# tviic2d6mddr register map
Vendor: Cypress Semiconductor; Series: tviic2d6mddr; File version: 1.0
CPU: CM7 r0p1, little endian, MPU, FPU, VTOR, 3 interrupt priority bits
Registers are 32-bit, read-write, reset 0x0 unless marked. A register's access mark holds for its fields unless they carry their own. Offsets are from the block's base; [hi:lo] are bit positions; lines under a group give offsets from that group; {n}, {i} and the like mark numbered series.

## LPDDR40 (part 5 of 5) — LPDDR4
Base 0x404A0000
0x4000 EMPU group — EMPU configuration
  {0x2000+0x40*j} EMPU_STRUCT[{j}] (j=0..7) group — EMPU structures.
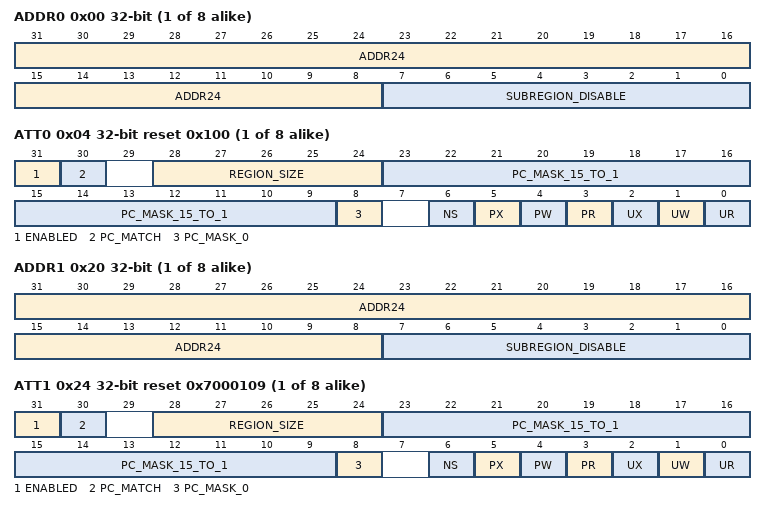
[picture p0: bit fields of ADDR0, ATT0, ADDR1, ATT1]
    0x00 ADDR0 reset not defined — EMPU region address 0 (slave structure)
      [31:8] ADDR24 — This field specifies the most significant bits of the 32-bit address of an address region. The region size is defined by ATT0.REGION_SIZE. A region of n Byte is always n Byte aligned. As a result, some of the lesser significant address bits of ADDR24 may be ignored in determining whether a bus transfer address is within an address region. E.g., a 64 KByte address region (REGION_SIZE is '15') is 64 KByte aligned, and ADDR24[7:0] are ignored.
      [7:0] SUBREGION_DISABLE — This field is used to individually disabled the eight equally sized subregions in which a region is partitioned. Subregion disable: Bit 0: subregion 0 disable. Bit 1: subregion 1 disable. Bit 2: subregion 2 disable. Bit 3: subregion 3 disable. Bit 4: subregion 4 disable. Bit 5: subregion 5 disable. Bit 6: subregion 6 disable. Bit 7: subregion 7 disable. E.g., a 64 KByte address region (ATT0.REGION_SIZE is '15') has eight 8 KByte subregions. The access control as defined by ATT0 applies if the bus transfer address is within the address region AND the addressed subregion is NOT disabled. Note that the smallest region size is 256 B and the smallest subregion size is 32 B.
    0x04 ATT0 reset 0x100 (reset mask 0x80000100) — EMPU region attributes 0 (slave structure)
      [31] ENABLED — Region enable: '0': Disabled. A disabled region will never result in a match on the bus transfer address. '1': Enabled. Note: a disabled address region performs logic gating to reduce dynamic power consumption.
      [30] PC_MATCH — This field specifies if the PC field participates in the 'matching' process or the 'access evaluation' process: '0': PC field participates in 'access evaluation'. '1': PC field participates in 'matching'. Note that it is possible to define different access control for multiple protection contexts by using multiple protection structures with the same address region and PC_MATCH set to '1'.
      [28:24] REGION_SIZE — This field specifies the region size: '0'-'6': Undefined. '7': 256 B region '8': 512 B region '9': 1 KB region '10': 2 KB region '11': 4 KB region '12': 8 KB region '13': 16 KB region '14': 32 KB region '15': 64 KB region '16': 128 KB region '17': 256 KB region '18': 512 KB region '19': 1 MB region '20': 2 MB region '21': 4 MB region '22': 8 MB region '23': 16 MB region '24': 32 MB region '25': 64 MB region '26': 128 MB region '27': 256 MB region '28': 512 MB region '39': 1 GB region '30': 2 GB region '31': 4 GB region
      [23:9] PC_MASK_15_TO_1 — This field specifies protection context identifier based access control. Bit i: protection context i+1 enable. If '0', protection context i+1 access is disabled; i.e. not allowed. If '1', protection context i+1 access is enabled; i.e. allowed.
      [8] PC_MASK_0 ro — This field specifies protection context identifier based access control for protection context '0'.
      [6] NS — Non-secure: '0': Secure (secure accesses allowed, non-secure access NOT allowed). '1': Non-secure (both secure and non-secure accesses allowed).
      [5] PX — Privileged execute enable: '0': Disabled (privileged, execute accesses are NOT allowed). '1': Enabled (privileged, execute accesses are allowed).
      [4] PW — Privileged write enable: '0': Disabled (privileged, write accesses are NOT allowed). '1': Enabled (privileged, write accesses are allowed).
      [3] PR — Privileged read enable: '0': Disabled (privileged, read accesses are NOT allowed). '1': Enabled (privileged, read accesses are allowed).
      [2] UX — User execute enable: '0': Disabled (user, execute accesses are NOT allowed). '1': Enabled (user, execute accesses are allowed).
      [1] UW — User write enable: '0': Disabled (user, write accesses are NOT allowed). '1': Enabled (user, write accesses are allowed).
      [0] UR — User read enable: '0': Disabled (user, read accesses are NOT allowed). '1': Enabled (user, read accesses are allowed).
    0x20 ADDR1 ro — EMPU region address 1 (master structure)
      [31:8] ADDR24 — This field specifies the most significant bits of the 32-bit address of an address region. 'ADDR_DEF1': base address of structure. Note: this field is read-only.
      [7:0] SUBREGION_DISABLE — This field is used to individually disabled the eight equally sized subregions in which a region is partitioned. Subregion disable: Bit 0: subregion 0 disable. Bit 1: subregion 1 disable. Bit 2: subregion 2 disable. Bit 3: subregion 3 disable. Bit 4: subregion 4 disable. Bit 5: subregion 5 disable. Bit 6: subregion 6 disable. Bit 7: subregion 7 disable. Two out of a total of eight 32 B subregions are enabled. These subregions includes region structures 0 and 1. Note: this field is read-only.
    0x24 ATT1 reset 0x7000109 (reset mask 0x9F00012D) — EMPU region attributes 1 (master structure)
      [31] ENABLED — Region enable: '0': Disabled. A disabled region will never result in a match on the bus transfer address. '1': Enabled.
      [30] PC_MATCH — This field specifies if the PC field participates in the 'matching' process or the 'access evaluation' process: '0': PC field participates in 'access evaluation'. '1': PC field participates in 'matching'. Note that it is possible to define different access control for multiple protection contexts by using multiple protection structures with the same address region and PC_MATCH set to '1'.
      [28:24] REGION_SIZE ro — This field specifies the region size: '7': 256 B region (8 32 B subregions) Note: this field is read-only.
      [23:9] PC_MASK_15_TO_1 — This field specifies protection context identifier based access control. Bit i: protection context i+1 enable. If '0', protection context i+1 access is disabled; i.e. not allowed. If '1', protection context i+1 access is enabled; i.e. allowed.
      [8] PC_MASK_0 ro — This field specifies protection context identifier based access control for protection context '0'.
      [6] NS — Non-secure: '0': Secure (secure accesses allowed, non-secure access NOT allowed). '1': Non-secure (both secure and non-secure accesses allowed).
      [5] PX ro — Privileged execute enable: '0': Disabled (privileged, execute accesses are NOT allowed). '1': Enabled (privileged, execute accesses are allowed). Note that this register is constant '0'; i.e. privileged execute accesses are NEVER allowed.
      [4] PW — Privileged write enable: '0': Disabled (privileged, write accesses are NOT allowed). '1': Enabled (privileged, write accesses are allowed).
      [3] PR ro — Privileged read enable: '0': Disabled (privileged, read accesses are NOT allowed). '1': Enabled (privileged, read accesses are allowed). Note that this register is constant '1'; i.e. privileged read accesses are ALWAYS allowed.
      [2] UX ro — User execute enable: '0': Disabled (user, execute accesses are NOT allowed). '1': Enabled (user, execute accesses are allowed). Note that this register is constant '0'; i.e. user execute accesses are NEVER allowed.
      [1] UW — User write enable: '0': Disabled (user, write accesses are NOT allowed). '1': Enabled (user, write accesses are allowed).
      [0] UR ro — User read enable: '0': Disabled (user, read accesses are NOT allowed). '1': Enabled (user, read accesses are allowed). Note that this register is constant '1'; i.e. user read accesses are ALWAYS allowed.
